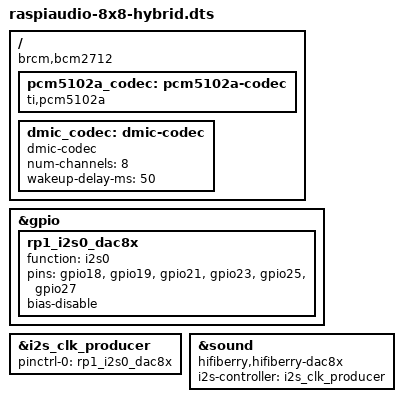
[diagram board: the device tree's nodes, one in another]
// Hybrid overlay for RaspiAudio 8xIN+8xOUT HAT
// Uses HiFiBerry DAC8x driver for 8-channel playback
// Adds DMIC codec for 8-channel capture
// Compatible with Raspberry Pi 5

/dts-v1/;
/plugin/;

/ {
    compatible = "brcm,bcm2712";

    // Reuse HiFiBerry fragments 0-3 for playback (DAC)
    fragment@0 {
        target = <&gpio>;
        __overlay__ {
            rp1_i2s0_dac8x: rp1_i2s0_dac8x {
                function = "i2s0";
                pins = "gpio18", "gpio19", "gpio21", "gpio23", "gpio25", "gpio27";
                bias-disable;
                status = "okay";
            };
        };
    };

    fragment@1 {
        target = <&i2s_clk_producer>;
        __overlay__ {
            pinctrl-names = "default";
            pinctrl-0 = <&rp1_i2s0_dac8x>;
            status = "okay";
        };
    };

    fragment@2 {
        target-path = "/";
        __overlay__ {
            pcm5102a_codec: pcm5102a-codec {
                #sound-dai-cells = <0>;
                compatible = "ti,pcm5102a";
                status = "okay";
            };
        };
    };

    // HiFiBerry DAC8x sound card (playback only)
    fragment@3 {
        target = <&sound>;
        __overlay__ {
            compatible = "hifiberry,hifiberry-dac8x";
            i2s-controller = <&i2s_clk_producer>;
            status = "okay";
        };
    };

    // Add DMIC codec for capture
    fragment@4 {
        target-path = "/";
        __overlay__ {
            dmic_codec: dmic-codec {
                #sound-dai-cells = <0>;
                compatible = "dmic-codec";
                num-channels = <8>;
                wakeup-delay-ms = <50>;
                status = "okay";
            };
        };
    };

    // TODO: Second sound card or additional DAI link for capture
    // This is the tricky part - we need to attach the DMIC to the same I2S controller
    // but as a separate capture stream. May require kernel driver modification.
};
